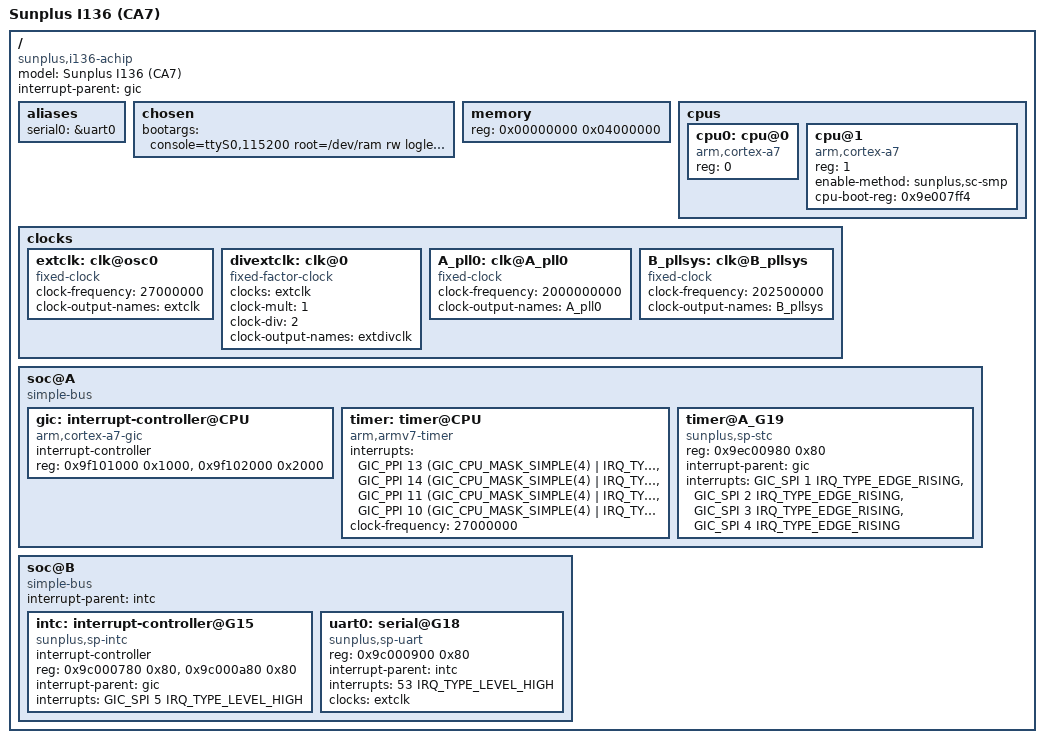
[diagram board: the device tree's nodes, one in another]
/dts-v1/;

#include "skeleton.dtsi"

#include <dt-bindings/interrupt-controller/arm-gic.h>

/ {
	model = "Sunplus I136 (CA7)";
	compatible = "sunplus,i136-achip";

	interrupt-parent = <&gic>;

	aliases {
		serial0 = &uart0;
	};

	chosen {
		bootargs = "console=ttyS0,115200 root=/dev/ram rw loglevel=8 earlyprintk";
	};

	memory {
		reg = <0x00000000 0x04000000>;
	};

	cpus {
		#address-cells = <1>;
		#size-cells = <0>;

		cpu0: cpu@0 {
			compatible = "arm,cortex-a7";
			device_type = "cpu";
			reg = <0>;
		};

		cpu@1 {
			compatible = "arm,cortex-a7";
			device_type = "cpu";
			reg = <1>;
			enable-method = "sunplus,sc-smp";
			cpu-boot-reg = <0x9e007ff4>;
		};
	};

	clocks {
		#address-cells = <1>;
		#size-cells = <1>;
		ranges;

		extclk: clk@osc0 {
			#clock-cells = <0>;
			compatible = "fixed-clock";
			clock-frequency = <27000000>;
			clock-output-names = "extclk";
		};

		divextclk: clk@0 {
			#clock-cells = <0>;
			compatible = "fixed-factor-clock";
			clocks  = <&extclk>;
			clock-mult = <1>;
			clock-div = <2>;
			clock-output-names = "extdivclk";
		};

		A_pll0: clk@A_pll0 {
			#clock-cells = <0>;
			compatible = "fixed-clock";
			clock-frequency = <2000000000>;
			clock-output-names = "A_pll0";
		};

		B_pllsys: clk@B_pllsys {
			#clock-cells = <0>;
			compatible = "fixed-clock";
			clock-frequency = <202500000>;
			clock-output-names = "B_pllsys";
		};
	};

	soc@A {
		compatible = "simple-bus";
		#address-cells = <1>;
		#size-cells = <1>;
		ranges;

		gic: interrupt-controller@CPU {
			compatible = "arm,cortex-a7-gic";
			interrupt-controller;
			#interrupt-cells = <3>;
			reg = <0x9f101000 0x1000>,
			      <0x9f102000 0x2000>;
		};

		timer: timer@CPU {
			compatible = "arm,armv7-timer";
			interrupts = <GIC_PPI 13 (GIC_CPU_MASK_SIMPLE(4) | IRQ_TYPE_LEVEL_LOW)>,
				     <GIC_PPI 14 (GIC_CPU_MASK_SIMPLE(4) | IRQ_TYPE_LEVEL_LOW)>,
				     <GIC_PPI 11 (GIC_CPU_MASK_SIMPLE(4) | IRQ_TYPE_LEVEL_LOW)>,
				     <GIC_PPI 10 (GIC_CPU_MASK_SIMPLE(4) | IRQ_TYPE_LEVEL_LOW)>;
			clock-frequency = <27000000>;
		};

		timer@A_G19 {
			compatible = "sunplus,sp-stc";
			reg = <0x9ec00980 0x80>;
			interrupt-parent = <&gic>;
			interrupts = <GIC_SPI 1 IRQ_TYPE_EDGE_RISING>, /* timer0 */
				     <GIC_SPI 2 IRQ_TYPE_EDGE_RISING>, /* timer1 */
				     <GIC_SPI 3 IRQ_TYPE_EDGE_RISING>, /* timer2 */
				     <GIC_SPI 4 IRQ_TYPE_EDGE_RISING>; /* timer3 */
		};
	};

	soc@B {
		compatible = "simple-bus";
		#address-cells = <1>;
		#size-cells = <1>;
		ranges;

		interrupt-parent = <&intc>;

		/* B modules */
		intc: interrupt-controller@G15 {
			compatible = "sunplus,sp-intc";
			interrupt-controller;
			#interrupt-cells = <2>;
			reg = <0x9c000780 0x80>, /* G15 */
			      <0x9c000a80 0x80>; /* G21 */
			interrupt-parent = <&gic>;
			interrupts = <GIC_SPI 5 IRQ_TYPE_LEVEL_HIGH>; /* EXT_INT0 */
		};

		uart0: serial@G18 {
			compatible = "sunplus,sp-uart";
			reg = <0x9c000900 0x80>;
			interrupt-parent = <&intc>;
			interrupts = <53 IRQ_TYPE_LEVEL_HIGH>;
			clocks = <&extclk>;
		};
	};
};
